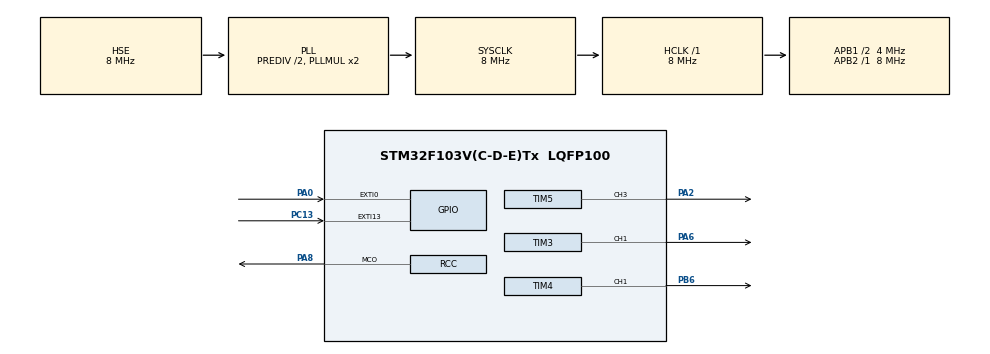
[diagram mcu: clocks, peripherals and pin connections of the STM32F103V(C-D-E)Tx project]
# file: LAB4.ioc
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Mcu.Family=STM32F1
Mcu.Name=STM32F103V(C-D-E)Tx
Mcu.Package=LQFP100
NVIC.EXTI0_IRQn=true\:0\:0\:false\:false\:true\:true\:true\:true
NVIC.EXTI15_10_IRQn=true\:0\:0\:false\:false\:true\:true\:true\:true
NVIC.PriorityGroup=NVIC_PRIORITYGROUP_4
OSC_IN.Mode=HSE-External-Oscillator
OSC_IN.Signal=RCC_OSC_IN
OSC_OUT.Mode=HSE-External-Oscillator
OSC_OUT.Signal=RCC_OSC_OUT
PA0-WKUP.Signal=GPXTI0
PA13.Mode=Serial_Wire
PA13.Signal=SYS_JTMS-SWDIO
PA14.Mode=Serial_Wire
PA14.Signal=SYS_JTCK-SWCLK
PA2.Signal=S_TIM5_CH3
PA6.GPIO_Speed=GPIO_SPEED_FREQ_HIGH
PA6.Signal=S_TIM3_CH1
PA8.GPIO_Speed=GPIO_SPEED_FREQ_HIGH
PA8.Mode=Clock-out
PA8.Signal=RCC_MCO
PB6.GPIO_Speed=GPIO_SPEED_FREQ_HIGH
PB6.Signal=S_TIM4_CH1
PC13-TAMPER-RTC.Signal=GPXTI13
PC14-OSC32_IN.Mode=LSE-External-Oscillator
PC14-OSC32_IN.Signal=RCC_OSC32_IN
PC15-OSC32_OUT.Mode=LSE-External-Oscillator
PC15-OSC32_OUT.Signal=RCC_OSC32_OUT
ProjectManager.HeapSize=0x200
ProjectManager.StackSize=0x400
ProjectManager.TargetToolchain=STM32CubeIDE
RCC.AHBFreq_Value=8000000
RCC.APB1CLKDivider=RCC_HCLK_DIV2
RCC.APB1Freq_Value=4000000
RCC.APB1TimFreq_Value=8000000
RCC.APB2Freq_Value=8000000
RCC.APB2TimFreq_Value=8000000
RCC.HCLKFreq_Value=8000000
RCC.HSEDivPLL=RCC_HSE_PREDIV_DIV2
RCC.PLLSourceVirtual=RCC_PLLSOURCE_HSE
RCC.SYSCLKFreq_VALUE=8000000
RCC.SYSCLKSource=RCC_SYSCLKSOURCE_PLLCLK
RCC.USBFreq_Value=8000000
SH.S_TIM3_CH1.0=TIM3_CH1,PWM Generation1 CH1
SH.S_TIM4_CH1.0=TIM4_CH1,PWM Generation1 CH1
SH.S_TIM5_CH3.0=TIM5_CH3,PWM Generation3 CH3
TIM3.Channel-PWM\ Generation1\ CH1=TIM_CHANNEL_1
TIM3.Period=199
TIM3.Prescaler=0
TIM3.Pulse-PWM\ Generation1\ CH1=120
TIM3.TIM_MasterOutputTrigger=TIM_TRGO_UPDATE
TIM3.TIM_MasterSlaveMode=TIM_MASTERSLAVEMODE_ENABLE
TIM4.Channel-PWM\ Generation1\ CH1=TIM_CHANNEL_1
TIM4.Period=40000/600-1
TIM4.Prescaler=0
TIM4.Pulse-PWM\ Generation1\ CH1=(40000/600)*0.6
TIM4.TIM_MasterOutputTrigger=TIM_TRGO_RESET
TIM4.TIM_MasterSlaveMode=TIM_MASTERSLAVEMODE_DISABLE
TIM5.Channel-PWM\ Generation3\ CH3=TIM_CHANNEL_3
TIM5.Period=1600-1
TIM5.Prescaler=100-1
TIM5.Pulse-PWM\ Generation3\ CH3=(1600-1)*0.075
VP_TIM3_VS_ClockSourceINT.Mode=Internal
VP_TIM4_VS_ClockSourceITR.Mode=TriggerSource_ITR2
VP_TIM4_VS_ControllerModeClock.Mode=Clock Mode
VP_TIM5_VS_ClockSourceINT.Mode=Internal
board=custom

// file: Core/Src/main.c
/* USER CODE BEGIN Header */
/**
  ******************************************************************************
  * @file           : main.c
  * @brief          : Main program body
  ******************************************************************************
  * @attention
  *
  * Copyright (c) 2025 STMicroelectronics.
  * All rights reserved.
  *
  * This software is licensed under terms that can be found in the LICENSE file
  * in the root directory of this software component.
  * If no LICENSE file comes with this software, it is provided AS-IS.
  *
  ******************************************************************************
  */
/* USER CODE END Header */
#include "main.h"

 TIM_HandleTypeDef htim3;
TIM_HandleTypeDef htim4;
TIM_HandleTypeDef htim5;

void SystemClock_Config(void);
static void MX_GPIO_Init(void);
static void MX_TIM3_Init(void);
static void MX_TIM4_Init(void);
static void MX_TIM5_Init(void);

int main(void)
{

  /* MCU Configuration--------------------------------------------------------*/

  /* Reset of all peripherals, Initializes the Flash interface and the Systick. */
  HAL_Init();

  /* Configure the system clock */
  SystemClock_Config();

  /* Initialize all configured peripherals */
  MX_GPIO_Init();
  MX_TIM3_Init();
  MX_TIM4_Init();
  MX_TIM5_Init();
  /* USER CODE BEGIN 2 */
  void run(){
	  //HAL_TIM_PWM_Start(&htim2, TIM_CHANNEL_1);
	  HAL_TIM_PWM_Start(&htim3, TIM_CHANNEL_1);
	  HAL_TIM_PWM_Start(&htim4, TIM_CHANNEL_1);
	  HAL_TIM_PWM_Start(&htim5, TIM_CHANNEL_3);
  }
//  void moter(){
//	  if(HAL_GPIO_ReadPin(GPIOC, GPIO_PIN_13)==1){
//		  HAL_Delay(100);
//		  Update_Pulse((1600-1)*0.1);
//	  }
//	  if(HAL_GPIO_ReadPin(GPIOA, GPIO_PIN_0)==1){
//		  HAL_Delay(100);
//		  Update_Pulse((1600-1)*0.05);
//	  }
//  }
  void Update_Pulse(uint16_t pulse) {
      HAL_TIM_PWM_Stop(&htim5, TIM_CHANNEL_3);
      __HAL_TIM_SET_COMPARE(&htim5, TIM_CHANNEL_3, pulse);
      HAL_TIM_PWM_Start(&htim5, TIM_CHANNEL_3);
  }
  /* USER CODE END 2 */

  /* Infinite loop */
  while (1)
  {
	  run();
	  if(HAL_GPIO_ReadPin(GPIOC, GPIO_PIN_13)==1 && HAL_GPIO_ReadPin(GPIOA, GPIO_PIN_0)==1){
		  HAL_Delay(100);
		  Update_Pulse((1600-1)*0.075);
	  }
  }
}

void SystemClock_Config(void)
{
  RCC_OscInitTypeDef RCC_OscInitStruct = {0};
  RCC_ClkInitTypeDef RCC_ClkInitStruct = {0};

  /** Initializes the RCC Oscillators according to the specified parameters
  * in the RCC_OscInitTypeDef structure.
  */
  RCC_OscInitStruct.OscillatorType = RCC_OSCILLATORTYPE_HSE;
  RCC_OscInitStruct.HSEState = RCC_HSE_ON;
  RCC_OscInitStruct.HSEPredivValue = RCC_HSE_PREDIV_DIV2;
  RCC_OscInitStruct.HSIState = RCC_HSI_ON;
  RCC_OscInitStruct.PLL.PLLState = RCC_PLL_ON;
  RCC_OscInitStruct.PLL.PLLSource = RCC_PLLSOURCE_HSE;
  RCC_OscInitStruct.PLL.PLLMUL = RCC_PLL_MUL2;
  if (HAL_RCC_OscConfig(&RCC_OscInitStruct) != HAL_OK)
  {
    Error_Handler();
  }

  /** Initializes the CPU, AHB and APB buses clocks
  */
  RCC_ClkInitStruct.ClockType = RCC_CLOCKTYPE_HCLK|RCC_CLOCKTYPE_SYSCLK
                              |RCC_CLOCKTYPE_PCLK1|RCC_CLOCKTYPE_PCLK2;
  RCC_ClkInitStruct.SYSCLKSource = RCC_SYSCLKSOURCE_PLLCLK;
  RCC_ClkInitStruct.AHBCLKDivider = RCC_SYSCLK_DIV1;
  RCC_ClkInitStruct.APB1CLKDivider = RCC_HCLK_DIV2;
  RCC_ClkInitStruct.APB2CLKDivider = RCC_HCLK_DIV1;

  if (HAL_RCC_ClockConfig(&RCC_ClkInitStruct, FLASH_LATENCY_0) != HAL_OK)
  {
    Error_Handler();
  }
  HAL_RCC_MCOConfig(RCC_MCO, RCC_MCO1SOURCE_SYSCLK, RCC_MCODIV_1);
}

static void MX_TIM3_Init(void)
{

  TIM_ClockConfigTypeDef sClockSourceConfig = {0};
  TIM_MasterConfigTypeDef sMasterConfig = {0};
  TIM_OC_InitTypeDef sConfigOC = {0};

  htim3.Instance = TIM3;
  htim3.Init.Prescaler = 0;
  htim3.Init.CounterMode = TIM_COUNTERMODE_UP;
  htim3.Init.Period = 199;
  htim3.Init.ClockDivision = TIM_CLOCKDIVISION_DIV1;
  htim3.Init.AutoReloadPreload = TIM_AUTORELOAD_PRELOAD_DISABLE;
  if (HAL_TIM_Base_Init(&htim3) != HAL_OK)
  {
    Error_Handler();
  }
  sClockSourceConfig.ClockSource = TIM_CLOCKSOURCE_INTERNAL;
  if (HAL_TIM_ConfigClockSource(&htim3, &sClockSourceConfig) != HAL_OK)
  {
    Error_Handler();
  }
  if (HAL_TIM_PWM_Init(&htim3) != HAL_OK)
  {
    Error_Handler();
  }
  sMasterConfig.MasterOutputTrigger = TIM_TRGO_UPDATE;
  sMasterConfig.MasterSlaveMode = TIM_MASTERSLAVEMODE_ENABLE;
  if (HAL_TIMEx_MasterConfigSynchronization(&htim3, &sMasterConfig) != HAL_OK)
  {
    Error_Handler();
  }
  sConfigOC.OCMode = TIM_OCMODE_PWM1;
  sConfigOC.Pulse = 120;
  sConfigOC.OCPolarity = TIM_OCPOLARITY_HIGH;
  sConfigOC.OCFastMode = TIM_OCFAST_DISABLE;
  if (HAL_TIM_PWM_ConfigChannel(&htim3, &sConfigOC, TIM_CHANNEL_1) != HAL_OK)
  {
    Error_Handler();
  }
  HAL_TIM_MspPostInit(&htim3);

}

static void MX_TIM4_Init(void)
{

  TIM_SlaveConfigTypeDef sSlaveConfig = {0};
  TIM_MasterConfigTypeDef sMasterConfig = {0};
  TIM_OC_InitTypeDef sConfigOC = {0};

  htim4.Instance = TIM4;
  htim4.Init.Prescaler = 0;
  htim4.Init.CounterMode = TIM_COUNTERMODE_UP;
  htim4.Init.Period = 40000/600-1;
  htim4.Init.ClockDivision = TIM_CLOCKDIVISION_DIV1;
  htim4.Init.AutoReloadPreload = TIM_AUTORELOAD_PRELOAD_DISABLE;
  if (HAL_TIM_Base_Init(&htim4) != HAL_OK)
  {
    Error_Handler();
  }
  if (HAL_TIM_PWM_Init(&htim4) != HAL_OK)
  {
    Error_Handler();
  }
  sSlaveConfig.SlaveMode = TIM_SLAVEMODE_EXTERNAL1;
  sSlaveConfig.InputTrigger = TIM_TS_ITR2;
  if (HAL_TIM_SlaveConfigSynchro(&htim4, &sSlaveConfig) != HAL_OK)
  {
    Error_Handler();
  }
  sMasterConfig.MasterOutputTrigger = TIM_TRGO_RESET;
  sMasterConfig.MasterSlaveMode = TIM_MASTERSLAVEMODE_DISABLE;
  if (HAL_TIMEx_MasterConfigSynchronization(&htim4, &sMasterConfig) != HAL_OK)
  {
    Error_Handler();
  }
  sConfigOC.OCMode = TIM_OCMODE_PWM1;
  sConfigOC.Pulse = (40000/600)*0.6;
  sConfigOC.OCPolarity = TIM_OCPOLARITY_HIGH;
  sConfigOC.OCFastMode = TIM_OCFAST_DISABLE;
  if (HAL_TIM_PWM_ConfigChannel(&htim4, &sConfigOC, TIM_CHANNEL_1) != HAL_OK)
  {
    Error_Handler();
  }
  HAL_TIM_MspPostInit(&htim4);

}

static void MX_TIM5_Init(void)
{

  TIM_ClockConfigTypeDef sClockSourceConfig = {0};
  TIM_MasterConfigTypeDef sMasterConfig = {0};
  TIM_OC_InitTypeDef sConfigOC = {0};

  htim5.Instance = TIM5;
  htim5.Init.Prescaler = 100-1;
  htim5.Init.CounterMode = TIM_COUNTERMODE_UP;
  htim5.Init.Period = 1600-1;
  htim5.Init.ClockDivision = TIM_CLOCKDIVISION_DIV1;
  htim5.Init.AutoReloadPreload = TIM_AUTORELOAD_PRELOAD_DISABLE;
  if (HAL_TIM_Base_Init(&htim5) != HAL_OK)
  {
    Error_Handler();
  }
  sClockSourceConfig.ClockSource = TIM_CLOCKSOURCE_INTERNAL;
  if (HAL_TIM_ConfigClockSource(&htim5, &sClockSourceConfig) != HAL_OK)
  {
    Error_Handler();
  }
  if (HAL_TIM_PWM_Init(&htim5) != HAL_OK)
  {
    Error_Handler();
  }
  sMasterConfig.MasterOutputTrigger = TIM_TRGO_RESET;
  sMasterConfig.MasterSlaveMode = TIM_MASTERSLAVEMODE_DISABLE;
  if (HAL_TIMEx_MasterConfigSynchronization(&htim5, &sMasterConfig) != HAL_OK)
  {
    Error_Handler();
  }
  sConfigOC.OCMode = TIM_OCMODE_PWM1;
  sConfigOC.Pulse = (1600-1)*0.075;
  sConfigOC.OCPolarity = TIM_OCPOLARITY_HIGH;
  sConfigOC.OCFastMode = TIM_OCFAST_DISABLE;
  if (HAL_TIM_PWM_ConfigChannel(&htim5, &sConfigOC, TIM_CHANNEL_3) != HAL_OK)
  {
    Error_Handler();
  }
  HAL_TIM_MspPostInit(&htim5);

}

static void MX_GPIO_Init(void)
{
  GPIO_InitTypeDef GPIO_InitStruct = {0};

  /* GPIO Ports Clock Enable */
  __HAL_RCC_GPIOC_CLK_ENABLE();
  __HAL_RCC_GPIOA_CLK_ENABLE();
  __HAL_RCC_GPIOB_CLK_ENABLE();

  /*Configure GPIO pin : PC13 */
  GPIO_InitStruct.Pin = GPIO_PIN_13;
  GPIO_InitStruct.Mode = GPIO_MODE_IT_RISING;
  GPIO_InitStruct.Pull = GPIO_NOPULL;
  HAL_GPIO_Init(GPIOC, &GPIO_InitStruct);

  /*Configure GPIO pin : PA0 */
  GPIO_InitStruct.Pin = GPIO_PIN_0;
  GPIO_InitStruct.Mode = GPIO_MODE_IT_RISING;
  GPIO_InitStruct.Pull = GPIO_NOPULL;
  HAL_GPIO_Init(GPIOA, &GPIO_InitStruct);

  /*Configure GPIO pin : PA8 */
  GPIO_InitStruct.Pin = GPIO_PIN_8;
  GPIO_InitStruct.Mode = GPIO_MODE_AF_PP;
  GPIO_InitStruct.Speed = GPIO_SPEED_FREQ_HIGH;
  HAL_GPIO_Init(GPIOA, &GPIO_InitStruct);

  /* EXTI interrupt init*/
  HAL_NVIC_SetPriority(EXTI0_IRQn, 0, 0);
  HAL_NVIC_EnableIRQ(EXTI0_IRQn);

  HAL_NVIC_SetPriority(EXTI15_10_IRQn, 0, 0);
  HAL_NVIC_EnableIRQ(EXTI15_10_IRQn);

}

void Error_Handler(void)
{
  __disable_irq();
  while (1)
  {
  }
}
